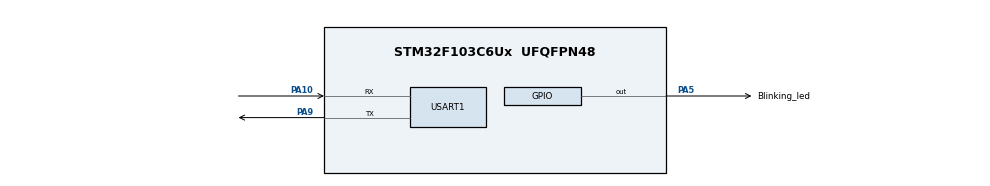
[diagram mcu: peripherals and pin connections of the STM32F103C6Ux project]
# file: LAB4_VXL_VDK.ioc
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IWDG.Prescaler=IWDG_PRESCALER_32
Mcu.Family=STM32F1
Mcu.Name=STM32F103C6Ux
Mcu.Package=UFQFPN48
NVIC.PriorityGroup=NVIC_PRIORITYGROUP_4
NVIC.TIM2_IRQn=true\:0\:0\:false\:false\:true\:true\:true
PA10.Mode=Asynchronous
PA10.Signal=USART1_RX
PA5.GPIO_Label=Blinking_led
PA5.Signal=GPIO_Output
PA9.Mode=Asynchronous
PA9.Signal=USART1_TX
ProjectManager.HeapSize=0x200
ProjectManager.StackSize=0x400
ProjectManager.TargetToolchain=STM32CubeIDE
RCC.APB1Freq_Value=8000000
RCC.APB2Freq_Value=8000000
TIM2.Period=9
TIM2.Prescaler=7999
USART1.VirtualMode=VM_ASYNC
VP_IWDG_VS_IWDG.Mode=IWDG_Activate
VP_SYS_VS_ND.Mode=No_Debug
VP_TIM2_VS_ClockSourceINT.Mode=Internal
board=custom

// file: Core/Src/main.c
/* USER CODE BEGIN Header */
/**
  ******************************************************************************
  * @file           : main.c
  * @brief          : Main program body
  ******************************************************************************
  * @attention
  *
  * <h2><center>&copy; Copyright (c) 2026 STMicroelectronics.
  * All rights reserved.</center></h2>
  *
  * This software component is licensed by ST under BSD 3-Clause license,
  * the "License"; You may not use this file except in compliance with the
  * License. You may obtain a copy of the License at:
  *                        opensource.org/licenses/BSD-3-Clause
  *
  ******************************************************************************
  */
/* USER CODE END Header */
#include "main.h"

/* USER CODE BEGIN Includes */
#include "scheduler.h"
#include <stdio.h>
/* USER CODE END Includes */

IWDG_HandleTypeDef hiwdg;

TIM_HandleTypeDef htim2;

UART_HandleTypeDef huart1;

/* USER CODE BEGIN PV */
uint32_t system_tick_count = 0;
/* USER CODE END PV */

void SystemClock_Config(void);
static void MX_GPIO_Init(void);
static void MX_TIM2_Init(void);
static void MX_IWDG_Init(void);
static void MX_USART1_UART_Init(void);
/* USER CODE BEGIN PFP */
uint32_t get_time(void);
void UART_Flush(void);
void Task_Heartbeat_LED(void);
void Task_Print_Time_10ms(void);
void Task_One_Shot_Demo(void);
void Task_0_5s(void);
void Task_1_0s(void);
void Task_1_5s(void);
void Task_2_0s(void);
void Task_2_5s(void);
/* USER CODE END PFP */

/* USER CODE BEGIN 0 */
// Trả về thời gian hệ thống thực tế tính bằng ms
uint32_t get_time(void) {
    return system_tick_count;
}

// Bộ đệm vòng (Ring Buffer) truyền UART phi chặn (Non-blocking)
#define UART_TX_BUF_SIZE 512
static uint8_t uart_tx_buf[UART_TX_BUF_SIZE];
static volatile uint16_t uart_tx_head = 0;
static volatile uint16_t uart_tx_tail = 0;

void UART_Flush(void) {
    while (uart_tx_tail != uart_tx_head) {
        if (__HAL_UART_GET_FLAG(&huart1, UART_FLAG_TXE)) {
            huart1.Instance->DR = uart_tx_buf[uart_tx_tail];
            uart_tx_tail = (uart_tx_tail + 1) % UART_TX_BUF_SIZE;
        } else {
            break;
        }
    }
}

// Chuyển hướng hàm printf ghi vào Ring Buffer phi chặn
int __io_putchar(int ch) {
    uint16_t next = (uart_tx_head + 1) % UART_TX_BUF_SIZE;
    while (next == uart_tx_tail) {
        // Buffer đầy, flush bớt ký tự ra UART
        UART_Flush();
    }
    uart_tx_buf[uart_tx_head] = (uint8_t)ch;
    uart_tx_head = next;
    UART_Flush();
    return ch;
}

void Task_Heartbeat_LED(void) {
    static GPIO_PinState led_state = GPIO_PIN_RESET;

    if (led_state == GPIO_PIN_RESET) {
        led_state = GPIO_PIN_SET;
    } else {
        led_state = GPIO_PIN_RESET;
    }

    HAL_GPIO_WritePin(Blinking_led_GPIO_Port, Blinking_led_Pin, led_state);
}

// 1. Task in ra timestamp mỗi 10ms
void Task_Print_Time_10ms(void) {
    printf("Time 10ms: %lu ms\r\n", get_time());
}

// 2. Task chạy một lần (One-shot) với delay dài (thêm trước khi vào while)
void Task_One_Shot_Demo(void) {
    printf("[ONE-SHOT TASK] Executed at timestamp: %lu ms\r\n", get_time());
}

// 3. 5 Task định kỳ yêu cầu của Lab 4 (0.5s, 1s, 1.5s, 2s, 2.5s)
void Task_0_5s(void) { printf("Task 0.5s executed at timestamp: %lu ms\r\n", get_time()); }
void Task_1_0s(void) { printf("Task 1.0s executed at timestamp: %lu ms\r\n", get_time()); }
void Task_1_5s(void) { printf("Task 1.5s executed at timestamp: %lu ms\r\n", get_time()); }
void Task_2_0s(void) { printf("Task 2.0s executed at timestamp: %lu ms\r\n", get_time()); }
void Task_2_5s(void) { printf("Task 2.5s executed at timestamp: %lu ms\r\n", get_time()); }

// Ngắt định kỳ TIM2 (10ms/lần)
void HAL_TIM_PeriodElapsedCallback(TIM_HandleTypeDef *htim) {
    if (htim->Instance == TIM2) {
        system_tick_count += 10;
        SCH_Update();

        // Refresh (đá) Watchdog định kỳ trong ngắt Timer để tránh hệ thống bị reset
        HAL_IWDG_Refresh(&hiwdg);
    }
}
/* USER CODE END 0 */

int main(void)
{

  /* MCU Configuration--------------------------------------------------------*/

  /* Reset of all peripherals, Initializes the Flash interface and the Systick. */
  HAL_Init();

  /* Configure the system clock */
  SystemClock_Config();

  /* Initialize all configured peripherals */
  MX_GPIO_Init();
  MX_TIM2_Init();
  MX_IWDG_Init();
  MX_USART1_UART_Init();
  /* USER CODE BEGIN 2 */
  // Khởi tạo bộ lập lịch
    SCH_Init();

    SCH_Add_Task(Task_Heartbeat_LED, 0, 1000);
    // Đăng ký Task One-shot (sau 3 giây = 3000ms) để kiểm chứng thực thi đồng thời
    SCH_Add_Task(Task_One_Shot_Demo, 3000, 0);

    // Đăng ký 5 Task định kỳ theo yêu cầu Lab 4: 0.5s, 1.0s, 1.5s, 2.0s, 2.5s
    SCH_Add_Task(Task_0_5s, 0, 500);
    SCH_Add_Task(Task_1_0s, 10, 1000);
    SCH_Add_Task(Task_1_5s, 20, 1500);
    SCH_Add_Task(Task_2_0s, 30, 2000);
    SCH_Add_Task(Task_2_5s, 40, 2500);

    // Khởi động Timer 2 sau khi đã nạp xong toàn bộ task ban đầu (tránh lệch tick khởi động)
    HAL_TIM_Base_Start_IT(&htim2);
  /* USER CODE END 2 */

  /* Infinite loop */
  /* USER CODE BEGIN WHILE */
  while (1)
  {
	 // Thực thi các tác vụ sẵn sàng trong hàng đợi
	 SCH_Dispatch_Tasks();

	 // Đẩy dữ liệu từ Ring Buffer ra UART phi chặn
	 UART_Flush();
    /* USER CODE END WHILE */

  }
}

void SystemClock_Config(void)
{
  RCC_OscInitTypeDef RCC_OscInitStruct = {0};
  RCC_ClkInitTypeDef RCC_ClkInitStruct = {0};

  /** Initializes the RCC Oscillators according to the specified parameters
  * in the RCC_OscInitTypeDef structure.
  */
  RCC_OscInitStruct.OscillatorType = RCC_OSCILLATORTYPE_HSI|RCC_OSCILLATORTYPE_LSI;
  RCC_OscInitStruct.HSIState = RCC_HSI_ON;
  RCC_OscInitStruct.HSICalibrationValue = RCC_HSICALIBRATION_DEFAULT;
  RCC_OscInitStruct.LSIState = RCC_LSI_ON;
  RCC_OscInitStruct.PLL.PLLState = RCC_PLL_NONE;
  if (HAL_RCC_OscConfig(&RCC_OscInitStruct) != HAL_OK)
  {
    Error_Handler();
  }
  /** Initializes the CPU, AHB and APB buses clocks
  */
  RCC_ClkInitStruct.ClockType = RCC_CLOCKTYPE_HCLK|RCC_CLOCKTYPE_SYSCLK
                              |RCC_CLOCKTYPE_PCLK1|RCC_CLOCKTYPE_PCLK2;
  RCC_ClkInitStruct.SYSCLKSource = RCC_SYSCLKSOURCE_HSI;
  RCC_ClkInitStruct.AHBCLKDivider = RCC_SYSCLK_DIV1;
  RCC_ClkInitStruct.APB1CLKDivider = RCC_HCLK_DIV1;
  RCC_ClkInitStruct.APB2CLKDivider = RCC_HCLK_DIV1;

  if (HAL_RCC_ClockConfig(&RCC_ClkInitStruct, FLASH_LATENCY_0) != HAL_OK)
  {
    Error_Handler();
  }
}

static void MX_IWDG_Init(void)
{

  hiwdg.Instance = IWDG;
  hiwdg.Init.Prescaler = IWDG_PRESCALER_32;
  hiwdg.Init.Reload = 4095;
  if (HAL_IWDG_Init(&hiwdg) != HAL_OK)
  {
    Error_Handler();
  }

}

static void MX_TIM2_Init(void)
{

  TIM_ClockConfigTypeDef sClockSourceConfig = {0};
  TIM_MasterConfigTypeDef sMasterConfig = {0};

  htim2.Instance = TIM2;
  htim2.Init.Prescaler = 7999;
  htim2.Init.CounterMode = TIM_COUNTERMODE_UP;
  htim2.Init.Period = 9;
  htim2.Init.ClockDivision = TIM_CLOCKDIVISION_DIV1;
  htim2.Init.AutoReloadPreload = TIM_AUTORELOAD_PRELOAD_DISABLE;
  if (HAL_TIM_Base_Init(&htim2) != HAL_OK)
  {
    Error_Handler();
  }
  sClockSourceConfig.ClockSource = TIM_CLOCKSOURCE_INTERNAL;
  if (HAL_TIM_ConfigClockSource(&htim2, &sClockSourceConfig) != HAL_OK)
  {
    Error_Handler();
  }
  sMasterConfig.MasterOutputTrigger = TIM_TRGO_RESET;
  sMasterConfig.MasterSlaveMode = TIM_MASTERSLAVEMODE_DISABLE;
  if (HAL_TIMEx_MasterConfigSynchronization(&htim2, &sMasterConfig) != HAL_OK)
  {
    Error_Handler();
  }

}

static void MX_USART1_UART_Init(void)
{

  huart1.Instance = USART1;
  huart1.Init.BaudRate = 115200;
  huart1.Init.WordLength = UART_WORDLENGTH_8B;
  huart1.Init.StopBits = UART_STOPBITS_1;
  huart1.Init.Parity = UART_PARITY_NONE;
  huart1.Init.Mode = UART_MODE_TX_RX;
  huart1.Init.HwFlowCtl = UART_HWCONTROL_NONE;
  huart1.Init.OverSampling = UART_OVERSAMPLING_16;
  if (HAL_UART_Init(&huart1) != HAL_OK)
  {
    Error_Handler();
  }

}

static void MX_GPIO_Init(void)
{
  GPIO_InitTypeDef GPIO_InitStruct = {0};

  /* GPIO Ports Clock Enable */
  __HAL_RCC_GPIOA_CLK_ENABLE();

  /*Configure GPIO pin Output Level */
  HAL_GPIO_WritePin(Blinking_led_GPIO_Port, Blinking_led_Pin, GPIO_PIN_RESET);

  /*Configure GPIO pin : Blinking_led_Pin */
  GPIO_InitStruct.Pin = Blinking_led_Pin;
  GPIO_InitStruct.Mode = GPIO_MODE_OUTPUT_PP;
  GPIO_InitStruct.Pull = GPIO_NOPULL;
  GPIO_InitStruct.Speed = GPIO_SPEED_FREQ_LOW;
  HAL_GPIO_Init(Blinking_led_GPIO_Port, &GPIO_InitStruct);

}

void Error_Handler(void)
{
  __disable_irq();
  while (1)
  {
  }
}

/************************ (C) COPYRIGHT STMicroelectronics *****END OF FILE****/
